# STM32F768 register map
File version: 1.2
Registers are 32-bit, read-write, reset 0x0 unless marked. A register's access mark holds for its fields unless they carry their own. Offsets are from the block's base; [hi:lo] are bit positions; {n}, {i} and the like mark numbered series.

## OTG_FS_PWRCLK — USB on the go full speed
Base 0x50000E00
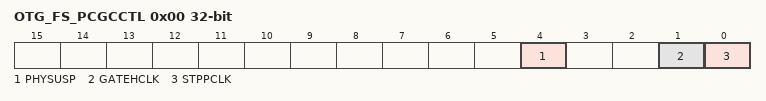
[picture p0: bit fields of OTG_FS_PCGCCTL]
0x00 OTG_FS_PCGCCTL — OTG_FS power and clock gating control register (OTG_FS_PCGCCTL)
  [4] PHYSUSP — PHY Suspended
  [1] GATEHCLK
  [0] STPPCLK — Stop PHY clock

## OTG_HS_PWRCLK — USB on the go high speed
Base 0x40040E00
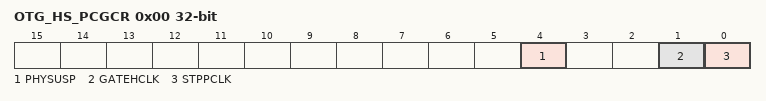
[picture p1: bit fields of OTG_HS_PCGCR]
0x00 OTG_HS_PCGCR — Power and clock gating control register
  [4] PHYSUSP — PHY suspended
  [1] GATEHCLK
  [0] STPPCLK — Stop PHY clock

## NVIC — Nested Vectored Interrupt Controller
Base 0xE000E100
{0x0+4i} ISER{i} (i=0..2) — Interrupt Set-Enable Register
  [31:0] SETENA
{0x80+4i} ICER{i} (i=0..2) — Interrupt Clear-Enable Register
  [31:0] CLRENA
{0x100+4i} ISPR{i} (i=0..2) — Interrupt Set-Pending Register
  [31:0] SETPEND
{0x180+4i} ICPR{i} (i=0..2) — Interrupt Clear-Pending Register
  [31:0] CLRPEND
{0x200+4i} IABR{i} ro (i=0..2) — Interrupt Active Bit Register
  [31:0] ACTIVE
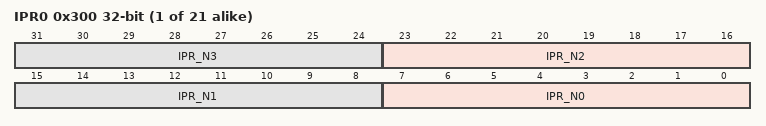
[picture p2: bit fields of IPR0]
{0x300+4i} IPR{i} (i=0..20) — Interrupt Priority Register
  [8n+7:8n] IPR_N{n} (n=0..3)
{0x300+4i} IPR{i} (i=21..28) — Interrupt Priority Register

## MPU — Memory protection unit
Base 0xE000ED90
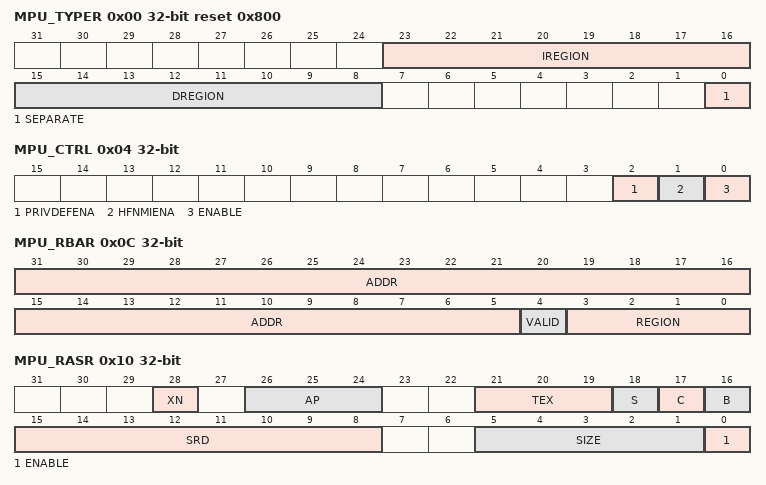
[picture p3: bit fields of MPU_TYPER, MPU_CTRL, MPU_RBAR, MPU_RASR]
0x00 MPU_TYPER ro reset 0x800 — MPU type register
  [23:16] IREGION — Number of MPU instruction regions
  [15:8] DREGION — Number of MPU data regions
  [0] SEPARATE — Separate flag
0x04 MPU_CTRL ro — MPU control register
  [2] PRIVDEFENA — Enable priviliged software access to default memory map
  [1] HFNMIENA — Enables the operation of MPU during hard fault
  [0] ENABLE — Enables the MPU
0x08 MPU_RNR — MPU region number register
  [7:0] REGION — MPU region
0x0C MPU_RBAR — MPU region base address register
  [31:5] ADDR — Region base address field
  [4] VALID — MPU region number valid
  [3:0] REGION — MPU region field
0x10 MPU_RASR — MPU region attribute and size register
  [28] XN — Instruction access disable bit
  [26:24] AP — Access permission
  [21:19] TEX — memory attribute
  [18] S — Shareable memory attribute
  [17] C — memory attribute
  [16] B — memory attribute
  [15:8] SRD — Subregion disable bits
  [5:1] SIZE — Size of the MPU protection region
  [0] ENABLE — Region enable bit.

## STK — SysTick timer
Base 0xE000E010
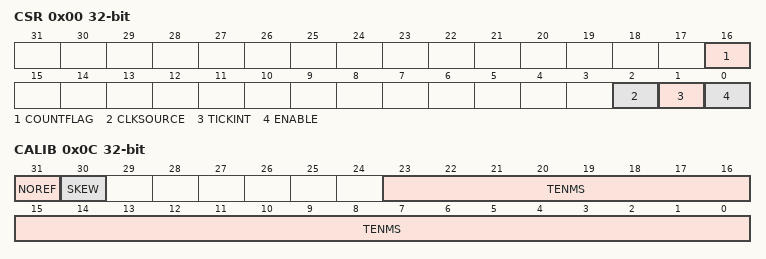
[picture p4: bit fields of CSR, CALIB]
0x00 CSR — SysTick control and status register
  [16] COUNTFLAG
  [2] CLKSOURCE — Clock source selection
  [1] TICKINT — SysTick exception request enable
  [0] ENABLE — Counter enable
0x04 RVR — SysTick reload value register
  [23:0] RELOAD — RELOAD value
0x08 CVR — SysTick current value register
  [23:0] CURRENT — Current counter value
0x0C CALIB — SysTick calibration value register
  [31] NOREF — NOREF flag. Reads as zero
  [30] SKEW — SKEW flag: Indicates whether the TENMS value is exact
  [23:0] TENMS — Calibration value

## NVIC_STIR — Nested vectored interrupt controller
Base 0xE000EF00
0x00 STIR — Software trigger interrupt register
  [8:0] INTID — Software generated interrupt ID

## FPU_CPACR — Floating point unit CPACR
Base 0xE000ED88
0x00 CPACR — Coprocessor access control register
  [23:20] CP

## SCB_ACTRL — System control block ACTLR
Base 0xE000E008
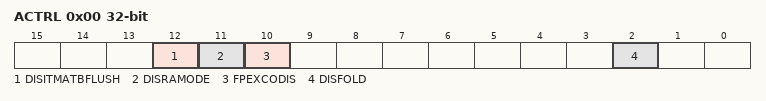
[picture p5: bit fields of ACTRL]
0x00 ACTRL — Auxiliary control register
  [12] DISITMATBFLUSH, [11] DISRAMODE, [10] FPEXCODIS, [2] DISFOLD

## FPU — Floting point unit
Base 0xE000EF34
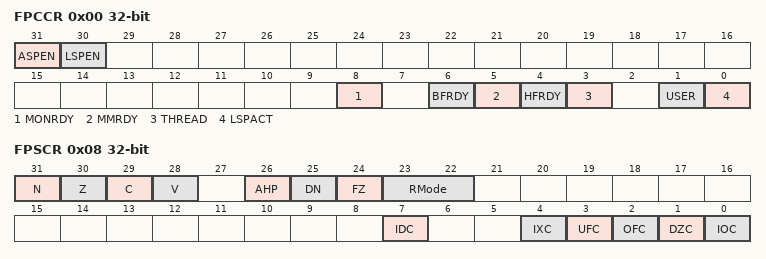
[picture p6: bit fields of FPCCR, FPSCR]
0x00 FPCCR — Floating-point context control register
  [31] ASPEN, [30] LSPEN, [8] MONRDY, [6] BFRDY, [5] MMRDY, [4] HFRDY, [3] THREAD, [1] USER, [0] LSPACT
0x04 FPCAR — Floating-point context address register
  [31:3] ADDRESS — Location of unpopulated floating-point
0x08 FPSCR — Floating-point status control register
  [31] N — Negative condition code flag
  [30] Z — Zero condition code flag
  [29] C — Carry condition code flag
  [28] V — Overflow condition code flag
  [26] AHP — Alternative half-precision control bit
  [25] DN — Default NaN mode control bit
  [24] FZ — Flush-to-zero mode control bit:
  [23:22] RMode — Rounding Mode control field
  [7] IDC — Input denormal cumulative exception bit.
  [4] IXC — Inexact cumulative exception bit
  [3] UFC — Underflow cumulative exception bit
  [2] OFC — Overflow cumulative exception bit
  [1] DZC — Division by zero cumulative exception bit.
  [0] IOC — Invalid operation cumulative exception bit
